# ATmega1281 device description
Architecture: AVR8; Family: megaAVR
Registers are 8-bit, access not given, no defined reset value unless marked. A register's access mark holds for its fields unless they carry their own. Offsets are from the block's base; [hi:lo] are bit positions.

## TWI — Two Wire Serial Interface
Instances: TWI 0x00
0xB8 TWBR — TWI Bit Rate register
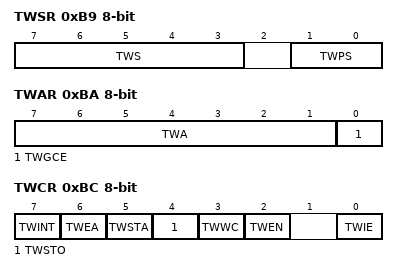
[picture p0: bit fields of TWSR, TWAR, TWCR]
0xB9 TWSR — TWI Status Register
  [7:3] TWS (bit 3 of the value upward) — TWI Status
  [1:0] TWPS — TWI Prescaler
    0=1; 1=4; 2=16; 3=64
0xBA TWAR — TWI (Slave) Address register
  [7:1] TWA — TWI (Slave) Address register Bits
  [0] TWGCE — TWI General Call Recognition Enable Bit
0xBB TWDR — TWI Data register
0xBC TWCR — TWI Control Register
  [7] TWINT — TWI Interrupt Flag
  [6] TWEA — TWI Enable Acknowledge Bit
  [5] TWSTA — TWI Start Condition Bit
  [4] TWSTO — TWI Stop Condition Bit
  [3] TWWC — TWI Write Collition Flag
  [2] TWEN — TWI Enable Bit
  [0] TWIE — TWI Interrupt Enable
0xBD TWAMR — TWI (Slave) Address Mask Register
  [7:1] TWAM

## SPI — Serial Peripheral Interface
Instances: SPI 0x00
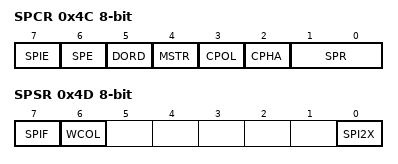
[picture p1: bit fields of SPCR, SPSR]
0x4C SPCR — SPI Control Register
  [7] SPIE — SPI Interrupt Enable
  [6] SPE — SPI Enable
  [5] DORD — Data Order
  [4] MSTR — Master/Slave Select
  [3] CPOL — Clock polarity
  [2] CPHA — Clock Phase
  [1:0] SPR — SPI Clock Rate Selects
    0=fosc/4; 1=fosc/16; 2=fosc/64; 3=fosc/128; 4=fosc/2; 5=fosc/8; 6=fosc/32; 7=fosc/64
0x4D SPSR — SPI Status Register
  [7] SPIF — SPI Interrupt Flag
  [6] WCOL — Write Collision Flag
  [0] SPI2X — Double SPI Speed Bit
0x4E SPDR — SPI Data Register

## PORTA — I/O Port
Instances: PORTA 0x00
0x20 PINA — Port A Input Pins
0x21 DDRA — Port A Data Direction Register
0x22 PORTA — Port A Data Register

## PORTB — I/O Port
Instances: PORTB 0x00
0x23 PINB — Port B Input Pins
0x24 DDRB — Port B Data Direction Register
0x25 PORTB — Port B Data Register

## PORTC — I/O Port
Instances: PORTC 0x00
0x26 PINC — Port C Input Pins
0x27 DDRC — Port C Data Direction Register
0x28 PORTC — Port C Data Register

## PORTD — I/O Port
Instances: PORTD 0x00
0x29 PIND — Port D Input Pins
0x2A DDRD — Port D Data Direction Register
0x2B PORTD — Port D Data Register

## PORTE — I/O Port
Instances: PORTE 0x00
0x2C PINE — Input Pins, Port E
0x2D DDRE — Data Direction Register, Port E
0x2E PORTE — Data Register, Port E

## PORTF — I/O Port
Instances: PORTF 0x00
0x2F PINF — Input Pins, Port F
0x30 DDRF — Data Direction Register, Port F
0x31 PORTF — Data Register, Port F

## PORTG — I/O Port
Instances: PORTG 0x00
0x32 PING bits used 5:0 — Input Pins, Port G
0x33 DDRG bits used 5:0 — Data Direction Register, Port G
0x34 PORTG bits used 5:0 — Data Register, Port G

## TC0 (TC8 module) — Timer/Counter, 8-bit
Instances: TC0 0x00
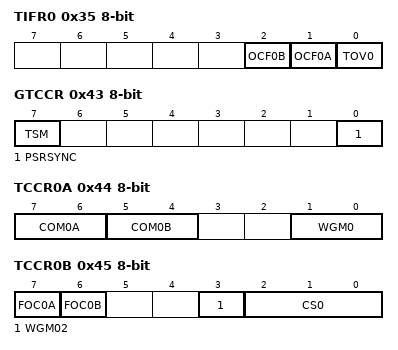
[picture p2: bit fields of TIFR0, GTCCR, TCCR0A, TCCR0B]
0x35 TIFR0 — Timer/Counter0 Interrupt Flag register
  [2] OCF0B — Timer/Counter0 Output Compare Flag 0B
  [1] OCF0A — Timer/Counter0 Output Compare Flag 0A
  [0] TOV0 — Timer/Counter0 Overflow Flag
0x43 GTCCR — General Timer/Counter Control Register
  [7] TSM — Timer/Counter Synchronization Mode
  [0] PSRSYNC — Prescaler Reset Timer/Counter1 and Timer/Counter0
0x44 TCCR0A — Timer/Counter Control Register A
  [7:6] COM0A — Compare Output Mode, Phase Correct PWM Mode
  [5:4] COM0B — Compare Output Mode, Fast PWm
  [1:0] WGM0 — Waveform Generation Mode
0x45 TCCR0B — Timer/Counter Control Register B
  [7] FOC0A — Force Output Compare A
  [6] FOC0B — Force Output Compare B
  [3] WGM02
  [2:0] CS0 — Clock Select
    0=No Clock Source (Stopped); 1=Running, No Prescaling; 2=Running, CLK/8; 3=Running, CLK/64; 4=Running, CLK/256; 5=Running, CLK/1024; 6=Running, ExtClk Tx Falling Edge; 7=Running, ExtClk Tx Rising Edge
0x46 TCNT0 — Timer/Counter0
0x47 OCR0A — Timer/Counter0 Output Compare Register
0x48 OCR0B — Timer/Counter0 Output Compare Register
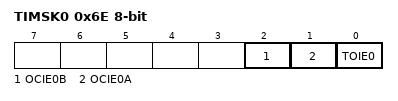
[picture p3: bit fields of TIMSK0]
0x6E TIMSK0 — Timer/Counter0 Interrupt Mask Register
  [2] OCIE0B — Timer/Counter0 Output Compare Match B Interrupt Enable
  [1] OCIE0A — Timer/Counter0 Output Compare Match A Interrupt Enable
  [0] TOIE0 — Timer/Counter0 Overflow Interrupt Enable
